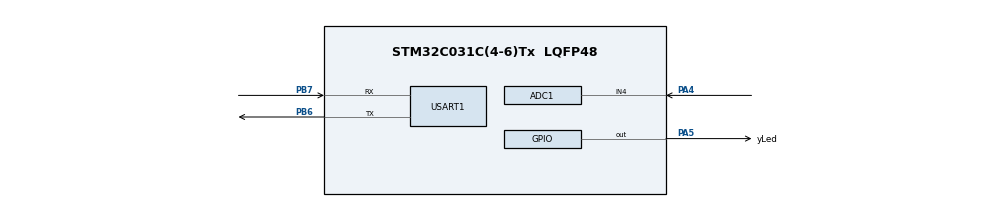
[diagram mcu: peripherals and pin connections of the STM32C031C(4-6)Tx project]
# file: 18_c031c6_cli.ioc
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ADC1.Channel-0\#ChannelRegularConversion=ADC_CHANNEL_4
ADC1.NbrOfConversionFlag=1
ADC1.Rank-0\#ChannelRegularConversion=1
ADC1.SamplingTime-0\#ChannelRegularConversion=ADC_SAMPLINGTIME_COMMON_1
ADC1.SamplingTimeCommon1=ADC_SAMPLETIME_12CYCLES_5
ADC1.SelectedChannel=ADC_CHANNEL_4
ADC1.master=1
Mcu.Family=STM32C0
Mcu.Name=STM32C031C(4-6)Tx
Mcu.Package=LQFP48
NVIC.TIM14_IRQn=true\:0\:0\:false\:false\:true\:true\:true\:true
NVIC.USART1_IRQn=true\:0\:0\:false\:false\:true\:true\:true\:true
PA13.Mode=Serial_Wire
PA13.Signal=DEBUG_SWDIO
PA14-BOOT0.Mode=Serial_Wire
PA14-BOOT0.Signal=DEBUG_SWCLK
PA4.Mode=IN4
PA4.Signal=ADC1_IN4
PA5.GPIO_Label=yLed
PA5.Signal=GPIO_Output
PB6.Mode=Asynchronous
PB6.Signal=USART1_TX
PB7.Mode=Asynchronous
PB7.Signal=USART1_RX
PC14-OSCX_IN\ (PC14).Mode=LSE-External-Oscillator
PC14-OSCX_IN\ (PC14).Signal=RCC_OSCX_IN
PC15-OSCX_OUT\ (PC15).Mode=LSE-External-Oscillator
PC15-OSCX_OUT\ (PC15).Signal=RCC_OSCX_OUT
ProjectManager.HeapSize=0x200
ProjectManager.StackSize=0x400
ProjectManager.TargetToolchain=STM32CubeIDE
RCC.ADCFreq_Value=48000000
RCC.AHBFreq_Value=48000000
RCC.CortexFreq_Value=48000000
RCC.EXTERNAL_CLOCK_VALUE=12288000
RCC.HCLKFreq_Value=48000000
RCC.HSE_VALUE=8000000
RCC.HSISYSCLKDivider=RCC_HSI_DIV1
RCC.HSI_VALUE=48000000
RCC.PREFETCH_ENABLE=1
RCC.RTCClockSelection=RCC_RTCCLKSOURCE_LSE
RCC.SYSCLKFreq_VALUE=48000000
RTC.Format=RTC_FORMAT_BIN
TIM14.Period=1000-1
TIM14.Prescaler=48-1
USART1.VirtualMode-Asynchronous=VM_ASYNC
VP_RTC_VS_RTC_Activate.Mode=RTC_Enabled
VP_RTC_VS_RTC_Calendar.Mode=RTC_Calendar
VP_TIM14_VS_ClockSourceINT.Mode=Enable_Timer
board=custom

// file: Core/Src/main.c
/* USER CODE BEGIN Header */
/**
  ******************************************************************************
  * @file           : main.c
  * @brief          : Main program body
  ******************************************************************************
  * @attention
  *
  * Copyright (c) 2024 STMicroelectronics.
  * All rights reserved.
  *
  * This software is licensed under terms that can be found in the LICENSE file
  * in the root directory of this software component.
  * If no LICENSE file comes with this software, it is provided AS-IS.
  *
  ******************************************************************************
  */
/* USER CODE END Header */
#include "main.h"

/* USER CODE BEGIN Includes */
#include "app.h"

/* USER CODE END Includes */

ADC_HandleTypeDef hadc1;

RTC_HandleTypeDef hrtc;

TIM_HandleTypeDef htim14;

UART_HandleTypeDef huart1;

void SystemClock_Config(void);
static void MX_GPIO_Init(void);
static void MX_ADC1_Init(void);
static void MX_USART1_UART_Init(void);
static void MX_TIM14_Init(void);
static void MX_RTC_Init(void);

int main(void)
{

  /* MCU Configuration--------------------------------------------------------*/

  /* Reset of all peripherals, Initializes the Flash interface and the Systick. */
  HAL_Init();

  /* Configure the system clock */
  SystemClock_Config();

  /* Initialize all configured peripherals */
  MX_GPIO_Init();
  MX_ADC1_Init();
  MX_USART1_UART_Init();
  MX_TIM14_Init();
  MX_RTC_Init();
  /* USER CODE BEGIN 2 */

  appInit();
  /* USER CODE END 2 */

  /* Infinite loop */
  /* USER CODE BEGIN WHILE */
  while (1)
  {
	  appMain();
    /* USER CODE END WHILE */

  }
}

void SystemClock_Config(void)
{
  RCC_OscInitTypeDef RCC_OscInitStruct = {0};
  RCC_ClkInitTypeDef RCC_ClkInitStruct = {0};

  /** Configure LSE Drive Capability
  */
  __HAL_RCC_LSEDRIVE_CONFIG(RCC_LSEDRIVE_LOW);

  /** Initializes the RCC Oscillators according to the specified parameters
  * in the RCC_OscInitTypeDef structure.
  */
  RCC_OscInitStruct.OscillatorType = RCC_OSCILLATORTYPE_HSI|RCC_OSCILLATORTYPE_LSE;
  RCC_OscInitStruct.LSEState = RCC_LSE_ON;
  RCC_OscInitStruct.HSIState = RCC_HSI_ON;
  RCC_OscInitStruct.HSIDiv = RCC_HSI_DIV1;
  RCC_OscInitStruct.HSICalibrationValue = RCC_HSICALIBRATION_DEFAULT;
  if (HAL_RCC_OscConfig(&RCC_OscInitStruct) != HAL_OK)
  {
    Error_Handler();
  }

  /** Initializes the CPU, AHB and APB buses clocks
  */
  RCC_ClkInitStruct.ClockType = RCC_CLOCKTYPE_HCLK|RCC_CLOCKTYPE_SYSCLK
                              |RCC_CLOCKTYPE_PCLK1;
  RCC_ClkInitStruct.SYSCLKSource = RCC_SYSCLKSOURCE_HSI;
  RCC_ClkInitStruct.SYSCLKDivider = RCC_SYSCLK_DIV1;
  RCC_ClkInitStruct.AHBCLKDivider = RCC_HCLK_DIV1;
  RCC_ClkInitStruct.APB1CLKDivider = RCC_APB1_DIV1;

  if (HAL_RCC_ClockConfig(&RCC_ClkInitStruct, FLASH_LATENCY_1) != HAL_OK)
  {
    Error_Handler();
  }
}

static void MX_ADC1_Init(void)
{

  ADC_ChannelConfTypeDef sConfig = {0};

  /** Configure the global features of the ADC (Clock, Resolution, Data Alignment and number of conversion)
  */
  hadc1.Instance = ADC1;
  hadc1.Init.ClockPrescaler = ADC_CLOCK_SYNC_PCLK_DIV2;
  hadc1.Init.Resolution = ADC_RESOLUTION_12B;
  hadc1.Init.DataAlign = ADC_DATAALIGN_RIGHT;
  hadc1.Init.ScanConvMode = ADC_SCAN_DISABLE;
  hadc1.Init.EOCSelection = ADC_EOC_SINGLE_CONV;
  hadc1.Init.LowPowerAutoWait = DISABLE;
  hadc1.Init.LowPowerAutoPowerOff = DISABLE;
  hadc1.Init.ContinuousConvMode = DISABLE;
  hadc1.Init.NbrOfConversion = 1;
  hadc1.Init.DiscontinuousConvMode = DISABLE;
  hadc1.Init.ExternalTrigConv = ADC_SOFTWARE_START;
  hadc1.Init.ExternalTrigConvEdge = ADC_EXTERNALTRIGCONVEDGE_NONE;
  hadc1.Init.DMAContinuousRequests = DISABLE;
  hadc1.Init.Overrun = ADC_OVR_DATA_PRESERVED;
  hadc1.Init.SamplingTimeCommon1 = ADC_SAMPLETIME_12CYCLES_5;
  hadc1.Init.SamplingTimeCommon2 = ADC_SAMPLETIME_1CYCLE_5;
  hadc1.Init.OversamplingMode = DISABLE;
  hadc1.Init.TriggerFrequencyMode = ADC_TRIGGER_FREQ_HIGH;
  if (HAL_ADC_Init(&hadc1) != HAL_OK)
  {
    Error_Handler();
  }

  /** Configure Regular Channel
  */
  sConfig.Channel = ADC_CHANNEL_4;
  sConfig.Rank = ADC_REGULAR_RANK_1;
  sConfig.SamplingTime = ADC_SAMPLINGTIME_COMMON_1;
  if (HAL_ADC_ConfigChannel(&hadc1, &sConfig) != HAL_OK)
  {
    Error_Handler();
  }

}

static void MX_RTC_Init(void)
{

  RTC_TimeTypeDef sTime = {0};
  RTC_DateTypeDef sDate = {0};

  /** Initialize RTC Only
  */
  hrtc.Instance = RTC;
  hrtc.Init.HourFormat = RTC_HOURFORMAT_24;
  hrtc.Init.AsynchPrediv = 127;
  hrtc.Init.SynchPrediv = 255;
  hrtc.Init.OutPut = RTC_OUTPUT_DISABLE;
  hrtc.Init.OutPutRemap = RTC_OUTPUT_REMAP_NONE;
  hrtc.Init.OutPutPolarity = RTC_OUTPUT_POLARITY_HIGH;
  hrtc.Init.OutPutType = RTC_OUTPUT_TYPE_OPENDRAIN;
  hrtc.Init.OutPutPullUp = RTC_OUTPUT_PULLUP_NONE;
  if (HAL_RTC_Init(&hrtc) != HAL_OK)
  {
    Error_Handler();
  }

  /** Initialize RTC and set the Time and Date
  */
  sTime.Hours = 0;
  sTime.Minutes = 0;
  sTime.Seconds = 0;
  sTime.SubSeconds = 0;
  sTime.DayLightSaving = RTC_DAYLIGHTSAVING_NONE;
  sTime.StoreOperation = RTC_STOREOPERATION_RESET;
  if (HAL_RTC_SetTime(&hrtc, &sTime, RTC_FORMAT_BIN) != HAL_OK)
  {
    Error_Handler();
  }
  sDate.WeekDay = RTC_WEEKDAY_MONDAY;
  sDate.Month = RTC_MONTH_JANUARY;
  sDate.Date = 1;
  sDate.Year = 0;

  if (HAL_RTC_SetDate(&hrtc, &sDate, RTC_FORMAT_BIN) != HAL_OK)
  {
    Error_Handler();
  }

}

static void MX_TIM14_Init(void)
{

  htim14.Instance = TIM14;
  htim14.Init.Prescaler = 48-1;
  htim14.Init.CounterMode = TIM_COUNTERMODE_UP;
  htim14.Init.Period = 1000-1;
  htim14.Init.ClockDivision = TIM_CLOCKDIVISION_DIV1;
  htim14.Init.AutoReloadPreload = TIM_AUTORELOAD_PRELOAD_DISABLE;
  if (HAL_TIM_Base_Init(&htim14) != HAL_OK)
  {
    Error_Handler();
  }

}

static void MX_USART1_UART_Init(void)
{

  huart1.Instance = USART1;
  huart1.Init.BaudRate = 115200;
  huart1.Init.WordLength = UART_WORDLENGTH_8B;
  huart1.Init.StopBits = UART_STOPBITS_1;
  huart1.Init.Parity = UART_PARITY_NONE;
  huart1.Init.Mode = UART_MODE_TX_RX;
  huart1.Init.HwFlowCtl = UART_HWCONTROL_NONE;
  huart1.Init.OverSampling = UART_OVERSAMPLING_16;
  huart1.Init.OneBitSampling = UART_ONE_BIT_SAMPLE_DISABLE;
  huart1.Init.ClockPrescaler = UART_PRESCALER_DIV1;
  huart1.AdvancedInit.AdvFeatureInit = UART_ADVFEATURE_NO_INIT;
  if (HAL_UART_Init(&huart1) != HAL_OK)
  {
    Error_Handler();
  }
  if (HAL_UARTEx_SetTxFifoThreshold(&huart1, UART_TXFIFO_THRESHOLD_1_8) != HAL_OK)
  {
    Error_Handler();
  }
  if (HAL_UARTEx_SetRxFifoThreshold(&huart1, UART_RXFIFO_THRESHOLD_1_8) != HAL_OK)
  {
    Error_Handler();
  }
  if (HAL_UARTEx_DisableFifoMode(&huart1) != HAL_OK)
  {
    Error_Handler();
  }

}

static void MX_GPIO_Init(void)
{
  GPIO_InitTypeDef GPIO_InitStruct = {0};

  /* GPIO Ports Clock Enable */
  __HAL_RCC_GPIOC_CLK_ENABLE();
  __HAL_RCC_GPIOA_CLK_ENABLE();
  __HAL_RCC_GPIOB_CLK_ENABLE();

  /*Configure GPIO pin Output Level */
  HAL_GPIO_WritePin(yLed_GPIO_Port, yLed_Pin, GPIO_PIN_RESET);

  /*Configure GPIO pin : yLed_Pin */
  GPIO_InitStruct.Pin = yLed_Pin;
  GPIO_InitStruct.Mode = GPIO_MODE_OUTPUT_PP;
  GPIO_InitStruct.Pull = GPIO_NOPULL;
  GPIO_InitStruct.Speed = GPIO_SPEED_FREQ_LOW;
  HAL_GPIO_Init(yLed_GPIO_Port, &GPIO_InitStruct);

}

void Error_Handler(void)
{
  __disable_irq();
  while (1)
  {
  }
}
